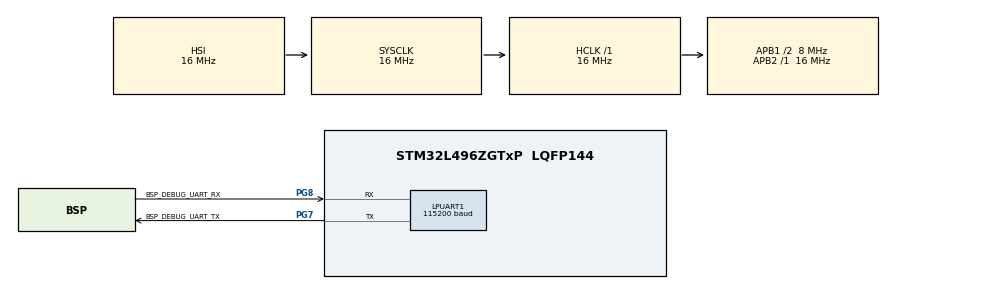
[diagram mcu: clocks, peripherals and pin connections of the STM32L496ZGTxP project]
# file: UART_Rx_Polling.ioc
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LPUART1.BaudRate=115200
LPUART1.WordLength=UART_WORDLENGTH_8B
Mcu.Family=STM32L4
Mcu.Name=STM32L496ZGTxP
Mcu.Package=LQFP144
NVIC.PriorityGroup=NVIC_PRIORITYGROUP_4
PG7.GPIO_Label=BSP_DEBUG_UART_TX
PG7.Mode=Asynchronous
PG7.Signal=LPUART1_TX
PG8.GPIO_Label=BSP_DEBUG_UART_RX
PG8.Mode=Asynchronous
PG8.Signal=LPUART1_RX
ProjectManager.HeapSize=0x200
ProjectManager.StackSize=0x400
ProjectManager.TargetToolchain=STM32CubeIDE
RCC.48MHZClocksFreq_Value=24000000
RCC.AHBFreq_Value=16000000
RCC.APB1CLKDivider=RCC_HCLK_DIV2
RCC.APB1Freq_Value=8000000
RCC.APB1TimFreq_Value=16000000
RCC.APB2Freq_Value=16000000
RCC.APB2TimFreq_Value=16000000
RCC.CortexFreq_Value=16000000
RCC.HCLKFreq_Value=16000000
RCC.HSE_VALUE=8000000
RCC.HSI48_VALUE=48000000
RCC.HSI_VALUE=16000000
RCC.LSE_VALUE=32768
RCC.MSI_VALUE=4000000
RCC.PLLMUL=RCC_PLL_MUL9
RCC.PRESCALERUSB=RCC_USBCLKSOURCE_PLL_DIV1_5
RCC.SYSCLKFreq_VALUE=16000000
RCC.SYSCLKSource=RCC_SYSCLKSOURCE_HSI
RCC.SYSCLKSourceVirtual=RCC_SYSCLKSOURCE_PLLCLK
RCC.USBFreq_Value=16000000
RCC.VCOOutputFreq_Value=32000000
board=NUCLEO-L496ZG-P

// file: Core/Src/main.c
/* USER CODE BEGIN Header */
/**
  ******************************************************************************
  * @file           : main.c
  * @brief          : Main program body
  ******************************************************************************
  * @attention
  *
  * Copyright (c) 2024 STMicroelectronics.
  * All rights reserved.
  *
  * This software is licensed under terms that can be found in the LICENSE file
  * in the root directory of this software component.
  * If no LICENSE file comes with this software, it is provided AS-IS.
  *
  ******************************************************************************
  */
/* USER CODE END Header */
#include "main.h"
#include <stdio.h>
#include <string.h>

/* USER CODE BEGIN PM */
#define MAX_SIZE 10			//mocro for size of buffer
#define NEWLINE_CHAR '\n'	//macro for newline character
#define RETURN_CHAR  '\r'	//macro for return carriage
#define RX_BYTE_SIZE 1		//macro for receiving data size(byte by byte)

/* USER CODE END PM */

UART_HandleTypeDef hlpuart1;

/* USER CODE BEGIN PV */
//uint8_t rx_buffer[MAX_SIZE];
char rx_buffer[MAX_SIZE];			//rx buffer

uint8_t Index = 0;					//index for buffer
uint8_t print_buffer[MAX_SIZE];		//buffer to print data on terminal

/* USER CODE END PV */

void SystemClock_Config(void);
static void MX_GPIO_Init(void);
static void MX_LPUART1_UART_Init(void);

int main(void)
{

  /* MCU Configuration--------------------------------------------------------*/

  /* Reset of all peripherals, Initializes the Flash interface and the Systick. */
  HAL_Init();

  /* Configure the system clock */
  SystemClock_Config();

  /* Initialize all configured peripherals */
  MX_GPIO_Init();
  MX_LPUART1_UART_Init();

  /* Infinite loop */
  while (1)
  {

    /* USER CODE BEGIN 3 */
	  /* receive the data into rx buffer*/
	  if(HAL_UART_Receive(&hlpuart1, (uint8_t *)rx_buffer, RX_BYTE_SIZE, HAL_MAX_DELAY) == HAL_OK)
	  {
		  /* Store the data of rx_buffer into new buffer */
		  if(rx_buffer[0]!= RETURN_CHAR && rx_buffer[0] != NEWLINE_CHAR)
		  {
			  print_buffer[Index] = rx_buffer[0];
			  Index++;
		  }
		  /* print the buffer if rx_buffer encounters a newline character */
		  else if (rx_buffer[0] == NEWLINE_CHAR)
		  {
			  printf("%s\r\n", print_buffer);	//print the data on the terminal

			  /* Clear the buffer */
			 memset(print_buffer, 0, MAX_SIZE);
			 Index = 0;
		  }
		  /* Print using uart
		   * If want to print using uart then un-comment below line*/
//		  HAL_UART_Transmit(&hlpuart1, rx_buffer_new, 1, 1000);
	  }

  }
  /* USER CODE END 3 */
}

void SystemClock_Config(void)
{
  RCC_OscInitTypeDef RCC_OscInitStruct = {0};
  RCC_ClkInitTypeDef RCC_ClkInitStruct = {0};

  /** Configure the main internal regulator output voltage
  */
  if (HAL_PWREx_ControlVoltageScaling(PWR_REGULATOR_VOLTAGE_SCALE1) != HAL_OK)
  {
    Error_Handler();
  }

  /** Initializes the RCC Oscillators according to the specified parameters
  * in the RCC_OscInitTypeDef structure.
  */
  RCC_OscInitStruct.OscillatorType = RCC_OSCILLATORTYPE_HSI;
  RCC_OscInitStruct.HSIState = RCC_HSI_ON;
  RCC_OscInitStruct.HSICalibrationValue = RCC_HSICALIBRATION_DEFAULT;
  RCC_OscInitStruct.PLL.PLLState = RCC_PLL_NONE;
  if (HAL_RCC_OscConfig(&RCC_OscInitStruct) != HAL_OK)
  {
    Error_Handler();
  }

  /** Initializes the CPU, AHB and APB buses clocks
  */
  RCC_ClkInitStruct.ClockType = RCC_CLOCKTYPE_HCLK|RCC_CLOCKTYPE_SYSCLK
                              |RCC_CLOCKTYPE_PCLK1|RCC_CLOCKTYPE_PCLK2;
  RCC_ClkInitStruct.SYSCLKSource = RCC_SYSCLKSOURCE_HSI;
  RCC_ClkInitStruct.AHBCLKDivider = RCC_SYSCLK_DIV1;
  RCC_ClkInitStruct.APB1CLKDivider = RCC_HCLK_DIV2;
  RCC_ClkInitStruct.APB2CLKDivider = RCC_HCLK_DIV1;

  if (HAL_RCC_ClockConfig(&RCC_ClkInitStruct, FLASH_LATENCY_0) != HAL_OK)
  {
    Error_Handler();
  }
}

static void MX_LPUART1_UART_Init(void)
{

  hlpuart1.Instance = LPUART1;
  hlpuart1.Init.BaudRate = 115200;
  hlpuart1.Init.WordLength = UART_WORDLENGTH_8B;
  hlpuart1.Init.StopBits = UART_STOPBITS_1;
  hlpuart1.Init.Parity = UART_PARITY_NONE;
  hlpuart1.Init.Mode = UART_MODE_TX_RX;
  hlpuart1.Init.HwFlowCtl = UART_HWCONTROL_NONE;
  hlpuart1.Init.OneBitSampling = UART_ONE_BIT_SAMPLE_DISABLE;
  hlpuart1.AdvancedInit.AdvFeatureInit = UART_ADVFEATURE_NO_INIT;
  if (HAL_UART_Init(&hlpuart1) != HAL_OK)
  {
    Error_Handler();
  }

}

static void MX_GPIO_Init(void)
{

  /* GPIO Ports Clock Enable */
  __HAL_RCC_GPIOG_CLK_ENABLE();
  HAL_PWREx_EnableVddIO2();

}

void Error_Handler(void)
{
  __disable_irq();
  while (1)
  {
  }
}
